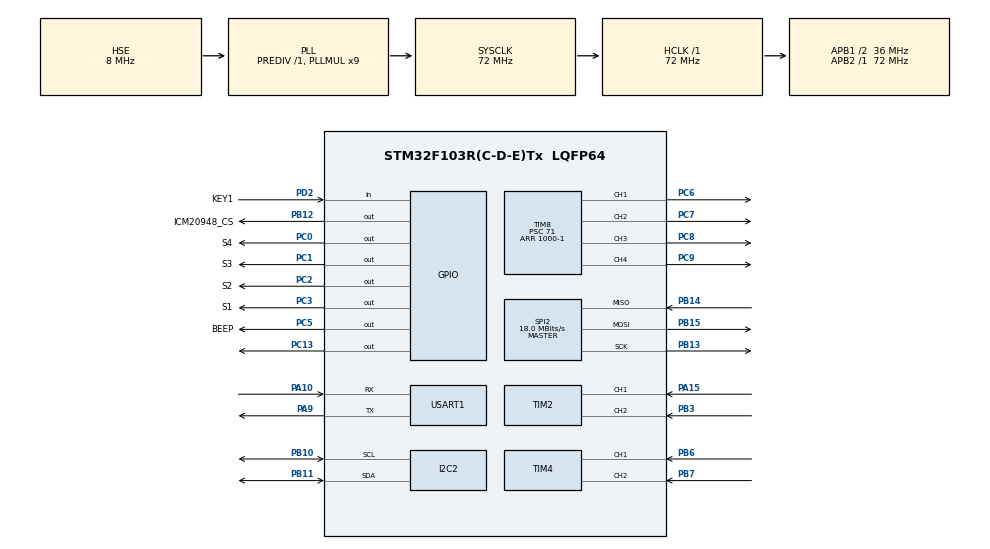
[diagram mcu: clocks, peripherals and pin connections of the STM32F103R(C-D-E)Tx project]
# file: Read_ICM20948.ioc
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Dma.Request0=USART1_TX
Dma.USART1_TX.0.Direction=DMA_MEMORY_TO_PERIPH
Dma.USART1_TX.0.Instance=DMA1_Channel4
Dma.USART1_TX.0.MemDataAlignment=DMA_MDATAALIGN_BYTE
Dma.USART1_TX.0.MemInc=DMA_MINC_ENABLE
Dma.USART1_TX.0.Mode=DMA_NORMAL
Dma.USART1_TX.0.PeriphDataAlignment=DMA_PDATAALIGN_BYTE
Dma.USART1_TX.0.PeriphInc=DMA_PINC_DISABLE
Dma.USART1_TX.0.Priority=DMA_PRIORITY_LOW
Mcu.Family=STM32F1
Mcu.Name=STM32F103R(C-D-E)Tx
Mcu.Package=LQFP64
NVIC.DMA1_Channel4_IRQn=true\:0\:0\:false\:false\:true\:false\:true\:true
NVIC.PriorityGroup=NVIC_PRIORITYGROUP_4
NVIC.TIM6_IRQn=true\:0\:0\:false\:false\:true\:true\:true\:true
NVIC.TIM7_IRQn=true\:0\:0\:false\:false\:true\:true\:true\:true
NVIC.USART1_IRQn=true\:0\:0\:false\:false\:true\:true\:true\:true
PA10.Mode=Asynchronous
PA10.Signal=USART1_RX
PA13.Mode=Serial_Wire
PA13.Signal=SYS_JTMS-SWDIO
PA14.Mode=Serial_Wire
PA14.Signal=SYS_JTCK-SWCLK
PA15.Signal=S_TIM2_CH1_ETR
PA9.Mode=Asynchronous
PA9.Signal=USART1_TX
PB10.Mode=I2C
PB10.Signal=I2C2_SCL
PB11.Mode=I2C
PB11.Signal=I2C2_SDA
PB12.GPIO_Label=ICM20948_CS
PB12.Signal=GPIO_Output
PB13.Mode=Full_Duplex_Master
PB13.Signal=SPI2_SCK
PB14.Mode=Full_Duplex_Master
PB14.Signal=SPI2_MISO
PB15.Mode=Full_Duplex_Master
PB15.Signal=SPI2_MOSI
PB3.Signal=S_TIM2_CH2
PB6.Signal=S_TIM4_CH1
PB7.Signal=S_TIM4_CH2
PC0.GPIO_Label=S4
PC0.GPIO_Speed=GPIO_SPEED_FREQ_HIGH
PC0.Signal=GPIO_Output
PC1.GPIO_Label=S3
PC1.GPIO_Speed=GPIO_SPEED_FREQ_HIGH
PC1.Signal=GPIO_Output
PC13-TAMPER-RTC.Signal=GPIO_Output
PC2.GPIO_Label=S2
PC2.GPIO_Speed=GPIO_SPEED_FREQ_HIGH
PC2.Signal=GPIO_Output
PC3.GPIO_Label=S1
PC3.GPIO_Speed=GPIO_SPEED_FREQ_HIGH
PC3.Signal=GPIO_Output
PC5.GPIO_Label=BEEP
PC5.Signal=GPIO_Output
PC6.Signal=S_TIM8_CH1
PC7.Signal=S_TIM8_CH2
PC8.Signal=S_TIM8_CH3
PC9.Signal=S_TIM8_CH4
PD0-OSC_IN.Mode=HSE-External-Oscillator
PD0-OSC_IN.Signal=RCC_OSC_IN
PD1-OSC_OUT.Mode=HSE-External-Oscillator
PD1-OSC_OUT.Signal=RCC_OSC_OUT
PD2.GPIO_Label=KEY1
PD2.GPIO_PuPd=GPIO_PULLUP
PD2.Signal=GPIO_Input
ProjectManager.HeapSize=0x200
ProjectManager.StackSize=0x400
ProjectManager.TargetToolchain=STM32CubeIDE
RCC.AHBFreq_Value=72000000
RCC.APB1CLKDivider=RCC_HCLK_DIV2
RCC.APB1Freq_Value=36000000
RCC.APB1TimFreq_Value=72000000
RCC.APB2Freq_Value=72000000
RCC.APB2TimFreq_Value=72000000
RCC.HCLKFreq_Value=72000000
RCC.PLLMUL=RCC_PLL_MUL9
RCC.PLLSourceVirtual=RCC_PLLSOURCE_HSE
RCC.SYSCLKFreq_VALUE=72000000
RCC.SYSCLKSource=RCC_SYSCLKSOURCE_PLLCLK
RCC.USBFreq_Value=72000000
SH.S_TIM2_CH1_ETR.0=TIM2_CH1,Encoder_Interface
SH.S_TIM2_CH2.0=TIM2_CH2,Encoder_Interface
SH.S_TIM4_CH1.0=TIM4_CH1,Encoder_Interface
SH.S_TIM4_CH2.0=TIM4_CH2,Encoder_Interface
SH.S_TIM8_CH1.0=TIM8_CH1,PWM Generation1 CH1
SH.S_TIM8_CH2.0=TIM8_CH2,PWM Generation2 CH2
SH.S_TIM8_CH3.0=TIM8_CH3,PWM Generation3 CH3
SH.S_TIM8_CH4.0=TIM8_CH4,PWM Generation4 CH4
SPI2.BaudRatePrescaler=SPI_BAUDRATEPRESCALER_2
SPI2.CalculateBaudRate=18.0 MBits/s
SPI2.Direction=SPI_DIRECTION_2LINES
SPI2.Mode=SPI_MODE_MASTER
SPI2.VirtualType=VM_MASTER
TIM6.Period=9999
TIM6.Prescaler=71
TIM7.AutoReloadPreload=TIM_AUTORELOAD_PRELOAD_ENABLE
TIM7.Period=9
TIM7.Prescaler=71
TIM8.AutoReloadPreload=TIM_AUTORELOAD_PRELOAD_ENABLE
TIM8.Channel-PWM\ Generation1\ CH1=TIM_CHANNEL_1
TIM8.Channel-PWM\ Generation2\ CH2=TIM_CHANNEL_2
TIM8.Channel-PWM\ Generation3\ CH3=TIM_CHANNEL_3
TIM8.Channel-PWM\ Generation4\ CH4=TIM_CHANNEL_4
TIM8.Period=1000-1
TIM8.Prescaler=71
USART1.VirtualMode=VM_ASYNC
VP_TIM6_VS_ClockSourceINT.Mode=Enable_Timer
VP_TIM7_VS_ClockSourceINT.Mode=Enable_Timer
VP_TIM8_VS_ClockSourceINT.Mode=Internal
board=custom

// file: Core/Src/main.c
/* USER CODE BEGIN Header */
/**
  ******************************************************************************
  * @file           : main.c
  * @brief          : Main program body
  ******************************************************************************
  * @attention
  *
  * Copyright (c) 2023 STMicroelectronics.
  * All rights reserved.
  *
  * This software is licensed under terms that can be found in the LICENSE file
  * in the root directory of this software component.
  * If no LICENSE file comes with this software, it is provided AS-IS.
  *
  ******************************************************************************
  */
/* USER CODE END Header */
#include "main.h"
#include "dma.h"
#include "i2c.h"
#include "spi.h"
#include "tim.h"
#include "usart.h"
#include "gpio.h"

/* USER CODE BEGIN Includes */
#include "bsp.h"
/* USER CODE END Includes */

void SystemClock_Config(void);

int main(void)
{

  /* MCU Configuration--------------------------------------------------------*/

  /* Reset of all peripherals, Initializes the Flash interface and the Systick. */
  HAL_Init();

  /* Configure the system clock */
  SystemClock_Config();

  /* Initialize all configured peripherals */
  MX_GPIO_Init();
  MX_DMA_Init();
  MX_USART1_UART_Init();
  MX_SPI2_Init();
  MX_TIM7_Init();
  MX_TIM8_Init();
  MX_TIM6_Init();
  MX_TIM2_Init();
  MX_TIM4_Init();
  MX_I2C2_Init();
  /* USER CODE BEGIN 2 */
  Bsp_Init();
  /* USER CODE END 2 */

  /* Infinite loop */
  /* USER CODE BEGIN WHILE */
  while (1)
  {
	Bsp_Loop();
    /* USER CODE END WHILE */

  }
}

void SystemClock_Config(void)
{
  RCC_OscInitTypeDef RCC_OscInitStruct = {0};
  RCC_ClkInitTypeDef RCC_ClkInitStruct = {0};

  /** Initializes the RCC Oscillators according to the specified parameters
  * in the RCC_OscInitTypeDef structure.
  */
  RCC_OscInitStruct.OscillatorType = RCC_OSCILLATORTYPE_HSE;
  RCC_OscInitStruct.HSEState = RCC_HSE_ON;
  RCC_OscInitStruct.HSEPredivValue = RCC_HSE_PREDIV_DIV1;
  RCC_OscInitStruct.HSIState = RCC_HSI_ON;
  RCC_OscInitStruct.PLL.PLLState = RCC_PLL_ON;
  RCC_OscInitStruct.PLL.PLLSource = RCC_PLLSOURCE_HSE;
  RCC_OscInitStruct.PLL.PLLMUL = RCC_PLL_MUL9;
  if (HAL_RCC_OscConfig(&RCC_OscInitStruct) != HAL_OK)
  {
    Error_Handler();
  }

  /** Initializes the CPU, AHB and APB buses clocks
  */
  RCC_ClkInitStruct.ClockType = RCC_CLOCKTYPE_HCLK|RCC_CLOCKTYPE_SYSCLK
                              |RCC_CLOCKTYPE_PCLK1|RCC_CLOCKTYPE_PCLK2;
  RCC_ClkInitStruct.SYSCLKSource = RCC_SYSCLKSOURCE_PLLCLK;
  RCC_ClkInitStruct.AHBCLKDivider = RCC_SYSCLK_DIV1;
  RCC_ClkInitStruct.APB1CLKDivider = RCC_HCLK_DIV2;
  RCC_ClkInitStruct.APB2CLKDivider = RCC_HCLK_DIV1;

  if (HAL_RCC_ClockConfig(&RCC_ClkInitStruct, FLASH_LATENCY_2) != HAL_OK)
  {
    Error_Handler();
  }
}

/* USER CODE BEGIN 4 */
//void HAL_TIM_PeriodElapsedCallback(TIM_HandleTypeDef *htim)
//{
//	if (htim->Instance == htim6.Instance)
//	{
//		Bsp_Loop();
//	}
//}
/* USER CODE END 4 */

void Error_Handler(void)
{
  __disable_irq();
  while (1)
  {
  }
}
